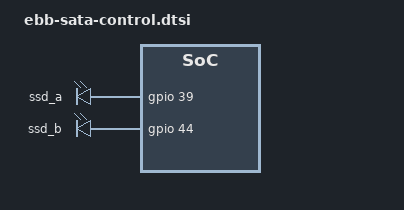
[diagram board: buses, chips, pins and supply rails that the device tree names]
/ {
    sata_control {
        compatible = "gpio-leds";

        ssd_a {
            gpios = <&gpio 39 0>;
            default-state = "off";
        };

        ssd_b {
            gpios = <&gpio 44 0>;
            default-state = "off";
        };
    };
};
